AUTOSAR XML (schema 4-2-2)
package /STELLANTIS/EPT/ASWCs
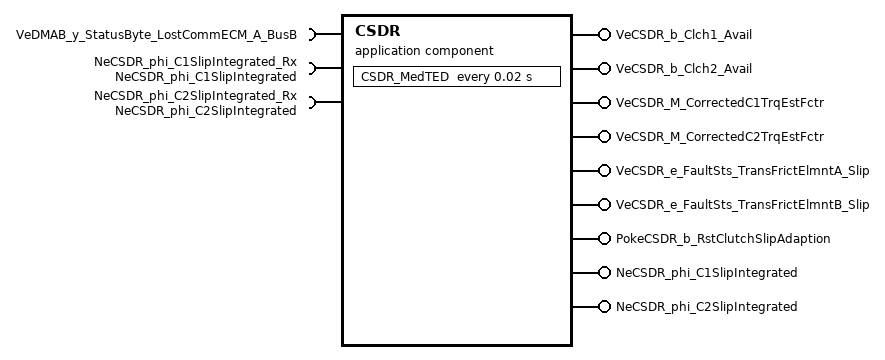
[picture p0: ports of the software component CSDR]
  application sw component type CSDR
    require port VeDMAB_y_StatusByte_LostCommECM_A_BusB: nonqueued-receiver-com-spec{data-element=Value, init-value=0}, required-interface=VeDMAB_y_StatusByte_LostCommECM_A_BusB
    7 x provide port:
      VeCSDR_b_Clch1_Avail: nonqueued-sender-com-spec{data-element=Value, init-value=0}, provided-interface=VeCSDR_b_Clch1_Avail
      VeCSDR_b_Clch2_Avail: nonqueued-sender-com-spec{data-element=Value, init-value=0}, provided-interface=VeCSDR_b_Clch2_Avail
      VeCSDR_M_CorrectedC1TrqEstFctr: nonqueued-sender-com-spec{data-element=Value, init-value=0}, provided-interface=VeCSDR_M_CorrectedC1TrqEstFctr
      VeCSDR_M_CorrectedC2TrqEstFctr: nonqueued-sender-com-spec{data-element=Value, init-value=0}, provided-interface=VeCSDR_M_CorrectedC2TrqEstFctr
      VeCSDR_e_FaultSts_TransFrictElmntA_Slip: nonqueued-sender-com-spec{data-element=Value, init-value=CeDFIB_e_Init}, provided-interface=VeCSDR_e_FaultSts_TransFrictElmntA_Slip
      VeCSDR_e_FaultSts_TransFrictElmntB_Slip: nonqueued-sender-com-spec{data-element=Value, init-value=CeDFIB_e_Init}, provided-interface=VeCSDR_e_FaultSts_TransFrictElmntB_Slip
      PokeCSDR_b_RstClutchSlipAdaption: server-com-spec=PokeCSDR_b_RstClutchSlipAdaption, provided-interface=PokeCSDR_b_RstClutchSlipAdaption
    require port NeCSDR_phi_C1SlipIntegrated_Rx: nv-require-com-spec{init-value=0, variable=NeCSDR_phi_C1SlipIntegrated}, required-interface=NeCSDR_phi_C1SlipIntegrated
    require port NeCSDR_phi_C2SlipIntegrated_Rx: nv-require-com-spec{init-value=0, variable=NeCSDR_phi_C2SlipIntegrated}, required-interface=NeCSDR_phi_C2SlipIntegrated
    provide port NeCSDR_phi_C1SlipIntegrated: nv-provide-com-spec{ram-block-init-value=0, variable=NeCSDR_phi_C1SlipIntegrated}, provided-interface=NeCSDR_phi_C1SlipIntegrated
    provide port NeCSDR_phi_C2SlipIntegrated: nv-provide-com-spec{ram-block-init-value=0, variable=NeCSDR_phi_C2SlipIntegrated}, provided-interface=NeCSDR_phi_C2SlipIntegrated
    behavior IB_CSDR: data-type-mapping=msADTtoIDTMapping, handle-termination-and-restart=NO-SUPPORT
      timing event Event_MedTED: start-on-event=CSDR_MedTED, period=0.02
      operation invoked event Event_PokeCSDR_b_RstClutchSlipAdaption: start-on-event=PokeCSDR_b_RstClutchSlipAdaption, operation=PokeCSDR_b_RstClutchSlipAdaption.PokeCSDR_b_RstClutchSlipAdaption
      4 x init event:
        Event_CSDR_ac_Init: start-on-event=CSDR_ac_Init
        Event_PUP: start-on-event=CSDR_PUP
        Event_PwrOn: start-on-event=CSDR_PwrOn
        Event_PwrOff: start-on-event=CSDR_PwrOff
      6 x runnable:
        CSDR_ac_Init
          data-send-points:
            access OUT_VeCSDR_e_FaultSts_TransFrictElmntA_Slip_Value: accessed-variable=VeCSDR_e_FaultSts_TransFrictElmntA_Slip.Value
            access OUT_VeCSDR_e_FaultSts_TransFrictElmntB_Slip_Value: accessed-variable=VeCSDR_e_FaultSts_TransFrictElmntB_Slip.Value
        CSDR_PUP
          data-send-points:
            access OUT_VeCSDR_b_Clch1_Avail_Value: accessed-variable=VeCSDR_b_Clch1_Avail.Value
            access OUT_VeCSDR_b_Clch2_Avail_Value: accessed-variable=VeCSDR_b_Clch2_Avail.Value
        CSDR_MedTED
          data-receive-point-by-arguments:
            access IN_VeDMAB_y_StatusByte_LostCommECM_A_BusB_Value: accessed-variable=VeDMAB_y_StatusByte_LostCommECM_A_BusB.Value
          data-send-points:
            6 x access:
              OUT_VeCSDR_b_Clch1_Avail_Value: accessed-variable=VeCSDR_b_Clch1_Avail.Value
              OUT_VeCSDR_b_Clch2_Avail_Value: accessed-variable=VeCSDR_b_Clch2_Avail.Value
              OUT_VeCSDR_M_CorrectedC1TrqEstFctr_Value: accessed-variable=VeCSDR_M_CorrectedC1TrqEstFctr.Value
              OUT_VeCSDR_M_CorrectedC2TrqEstFctr_Value: accessed-variable=VeCSDR_M_CorrectedC2TrqEstFctr.Value
              OUT_VeCSDR_e_FaultSts_TransFrictElmntA_Slip_Value: accessed-variable=VeCSDR_e_FaultSts_TransFrictElmntA_Slip.Value
              OUT_VeCSDR_e_FaultSts_TransFrictElmntB_Slip_Value: accessed-variable=VeCSDR_e_FaultSts_TransFrictElmntB_Slip.Value
        CSDR_PwrOn
          data-receive-point-by-arguments:
            access IN_NeCSDR_phi_C1SlipIntegrated_Rx_NeCSDR_phi_C1SlipIntegrated: accessed-variable=NeCSDR_phi_C1SlipIntegrated_Rx.NeCSDR_phi_C1SlipIntegrated
            access IN_NeCSDR_phi_C2SlipIntegrated_Rx_NeCSDR_phi_C2SlipIntegrated: accessed-variable=NeCSDR_phi_C2SlipIntegrated_Rx.NeCSDR_phi_C2SlipIntegrated
          data-send-points:
            4 x access:
              OUT_VeCSDR_M_CorrectedC1TrqEstFctr_Value: accessed-variable=VeCSDR_M_CorrectedC1TrqEstFctr.Value
              OUT_VeCSDR_M_CorrectedC2TrqEstFctr_Value: accessed-variable=VeCSDR_M_CorrectedC2TrqEstFctr.Value
              OUT_VeCSDR_e_FaultSts_TransFrictElmntA_Slip_Value: accessed-variable=VeCSDR_e_FaultSts_TransFrictElmntA_Slip.Value
              OUT_VeCSDR_e_FaultSts_TransFrictElmntB_Slip_Value: accessed-variable=VeCSDR_e_FaultSts_TransFrictElmntB_Slip.Value
        CSDR_PwrOff
          data-send-points:
            access OUT_NeCSDR_phi_C1SlipIntegrated_NeCSDR_phi_C1SlipIntegrated: accessed-variable=NeCSDR_phi_C1SlipIntegrated.NeCSDR_phi_C1SlipIntegrated
            access OUT_NeCSDR_phi_C2SlipIntegrated_NeCSDR_phi_C2SlipIntegrated: accessed-variable=NeCSDR_phi_C2SlipIntegrated.NeCSDR_phi_C2SlipIntegrated
        PokeCSDR_b_RstClutchSlipAdaption
      variation point proxy Variant_CSDR_1: category=CONDITION, condition-access=0
